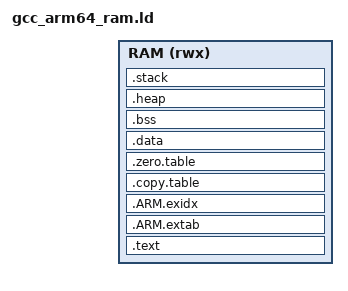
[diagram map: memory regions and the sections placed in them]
MEMORY
{
  RAM   (rwx) : ORIGIN = __RAM_BASE, LENGTH = __RAM_SIZE
}
ENTRY(Reset_Handler)

SECTIONS
{
  .text :
  {
    KEEP(*(.vectors))
    *(.text*)

    KEEP(*(.init))
    KEEP(*(.fini))

    /* .ctors */
    *crtbegin.o(.ctors)
    *crtbegin?.o(.ctors)
    *(EXCLUDE_FILE(*crtend?.o *crtend.o) .ctors)
    *(SORT(.ctors.*))
    *(.ctors)

    /* .dtors */
    *crtbegin.o(.dtors)
    *crtbegin?.o(.dtors)
    *(EXCLUDE_FILE(*crtend?.o *crtend.o) .dtors)
    *(SORT(.dtors.*))
    *(.dtors)

    *(.rodata*)

    KEEP(*(.eh_frame*))
  } > RAM
  .ARM.extab :
  {
    *(.ARM.extab* .gnu.linkonce.armextab.*)
  } > RAM

  __exidx_start = .;
  .ARM.exidx :
  {
    *(.ARM.exidx* .gnu.linkonce.armexidx.*)
  } > RAM
  __exidx_end = .;

  .copy.table :
  {
    . = ALIGN(16);
    __copy_table_start__ = .;
    LONG (__etext)
    LONG (__data_start__)
    LONG (__data_end__ - __data_start__)

      __copy_table_end__ = .;
  } > RAM

  .zero.table :
  {
    . = ALIGN(16);
    __zero_table_start__ = .;
    /* Add each additional bss section here */
/*
    LONG (__bss2_start__)
    LONG (__bss2_end__ - __bss2_start__)
*/
    __zero_table_end__ = .;
  } > RAM

  __etext = ALIGN(16);

  .data : AT (__etext)
  {
    __data_start__ = .;
    *(vtable)
    *(.data)
    *(.data.*)

    . = ALIGN(16);
    /* preinit data */
    PROVIDE_HIDDEN (__preinit_array_start = .);
    KEEP(*(.preinit_array))
    PROVIDE_HIDDEN (__preinit_array_end = .);

    . = ALIGN(16);
    /* init data */
    PROVIDE_HIDDEN (__init_array_start = .);
    KEEP(*(SORT(.init_array.*)))
    KEEP(*(.init_array))
    PROVIDE_HIDDEN (__init_array_end = .);

      . = ALIGN(16);
    /* finit data */
    PROVIDE_HIDDEN (__fini_array_start = .);
    KEEP(*(SORT(.fini_array.*)))
    KEEP(*(.fini_array))
    PROVIDE_HIDDEN (__fini_array_end = .);

    KEEP(*(.jcr*))
    . = ALIGN(16);
    /* All data end */
    __data_end__ = .;

  } > RAM

  .bss :
  {
    . = ALIGN(16);
    __bss_start__ = .;
    *(.bss)
    *(.bss.*)
    *(COMMON)
    . = ALIGN(16);
    __bss_end__ = .;
  } > RAM AT > RAM

  .heap (COPY) :
  {
    . = ALIGN(16);
    __end__ = .;
    PROVIDE(end = .);
    . = . + __HEAP_SIZE;
    . = ALIGN(16);
    __HeapLimit = .;
  } > RAM

  .stack (ORIGIN(RAM) + LENGTH(RAM) - __STACK_SIZE) (COPY) :
  {
    . = ALIGN(16);
    __StackLimit = .;
    . = . + __STACK_SIZE;
    . = ALIGN(16);
    __StackTop = .;
  } > RAM
  PROVIDE(__stack = __StackTop);

}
